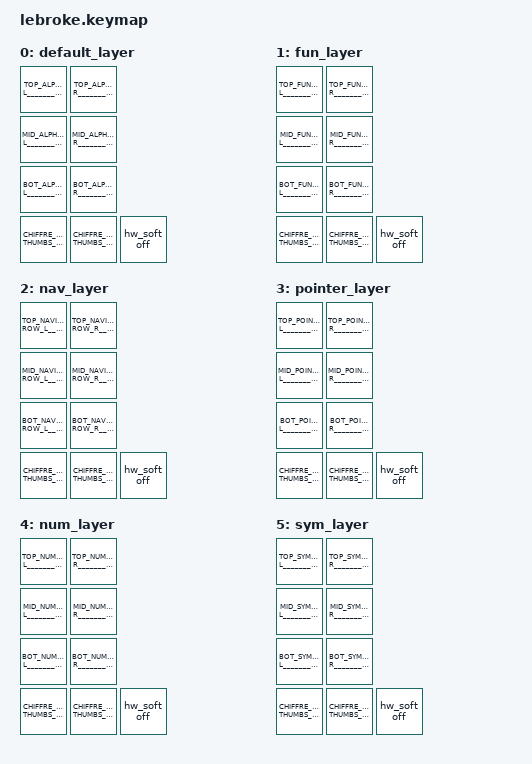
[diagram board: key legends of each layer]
#include <behaviors.dtsi>
#include <dt-bindings/zmk/keys.h>
#include <dt-bindings/zmk/bt.h>
#include <dt-bindings/zmk/pointing.h>
#include "shared/keymap-3x5.h"
#include "shared/behaviors.dtsi"

// Using layer taps on thumbs, having quick tap as well helps w/ repeating space/backspace
&lt { quick_tap_ms = <200>; };

/ {
	behaviors {
        hw_soft_off: hw_soft_off {
            compatible = "zmk,behavior-soft-off";
            #binding-cells = <0>;
            split-peripheral-off-on-press; // Turn peripheral off immediately for reliability (not applicable)
            hold-time-ms = <1500>; // Only turn off if the key is held for 1.5 seconds or longer.
        };
    };
    keymap {
        compatible = "zmk,keymap";
        default_layer {
            display-name = LABEL_ALPHAS;
            bindings = <
                _____________TOP_ALPHAS_ROW_L______________ _____________TOP_ALPHAS_ROW_R______________
                _____________MID_ALPHAS_ROW_L______________ _____________MID_ALPHAS_ROW_R______________
                _____________BOT_ALPHAS_ROW_L______________ _____________BOT_ALPHAS_ROW_R______________
                ___CHIFFRE_ALPHA3_THUMBS_L____ ___CHIFFRE_ALPHA3_THUMBS_R____              &hw_soft_off
            >;
        };

        fun_layer {
            display-name = LABEL_FUN;
            bindings = <
                _____________TOP_FUNCTION_ROW_L____________ _____________TOP_FUNCTION_ROW_R____________
                _____________MID_FUNCTION_ROW_L____________ _____________MID_FUNCTION_ROW_R____________
                _____________BOT_FUNCTION_ROW_L____________ _____________BOT_FUNCTION_ROW_R____________
				___CHIFFRE_FUN3_THUMBS_L____ ___CHIFFRE_FUN3_THUMBS_R____                  &hw_soft_off
            >;
        };

        nav_layer {
            display-name = LABEL_NAV;
            bindings = <
                ___________TOP_NAVIGATION_ROW_L____________ ___________TOP_NAVIGATION_ROW_R____________
                ___________MID_NAVIGATION_ROW_L____________ ___________MID_NAVIGATION_ROW_R____________
                ___________BOT_NAVIGATION_ROW_L____________ ___________BOT_NAVIGATION_ROW_R____________
				___CHIFFRE_NAV3_THUMBS_L____ ___CHIFFRE_NAV3_THUMBS_R____                  &hw_soft_off
            >;
        };

		pointer_layer {
            display-name = LABEL_POI;
            bindings = <
                _____________TOP_POINTER_ROW_L_____________ _____________TOP_POINTER_ROW_R_____________
                _____________MID_POINTER_ROW_L_____________ _____________MID_POINTER_ROW_R_____________
                _____________BOT_POINTER_ROW_L_____________ _____________BOT_POINTER_ROW_R_____________
				___CHIFFRE_POI3_THUMBS_L____ ___CHIFFRE_POI3_THUMBS_R____                  &hw_soft_off
            >;
        };

        num_layer {
            display-name = LABEL_NUM;
            bindings = <
                _____________TOP_NUMERAL_ROW_L_____________ _____________TOP_NUMERAL_ROW_R_____________
                _____________MID_NUMERAL_ROW_L_____________ _____________MID_NUMERAL_ROW_R_____________
                _____________BOT_NUMERAL_ROW_L_____________ _____________BOT_NUMERAL_ROW_R_____________
				___CHIFFRE_NUM3_THUMBS_L____ ___CHIFFRE_NUM3_THUMBS_R____                  &hw_soft_off
            >;
        };

        sym_layer {
            display-name = LABEL_SYM;
            bindings = <
                _____________TOP_SYMBOLS_ROW_L_____________ _____________TOP_SYMBOLS_ROW_R_____________
                _____________MID_SYMBOLS_ROW_L_____________ _____________MID_SYMBOLS_ROW_R_____________
                _____________BOT_SYMBOLS_ROW_L_____________ _____________BOT_SYMBOLS_ROW_R_____________
				___CHIFFRE_SYM3_THUMBS_L____ ___CHIFFRE_SYM3_THUMBS_R____                  &hw_soft_off
            >;
        };
    };
};



